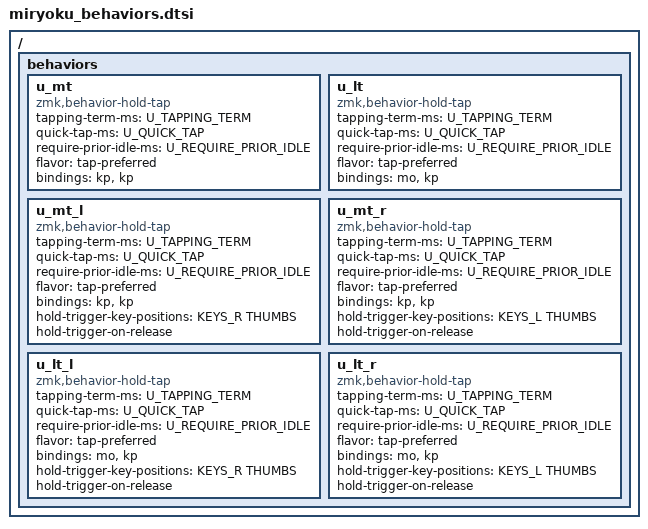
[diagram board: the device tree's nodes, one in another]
// Copyright 2022 Manna Harbour
// https://github.com/manna-harbour/miryoku

// Default key position definitions - can be overridden by keyboard-specific mappings
#if !defined(KEYS_L)
#define KEYS_L 0 1 2 3 4 10 11 12 13 14 20 21 22 23 24  // Left-hand keys
#endif
#if !defined(KEYS_R)
#define KEYS_R 5 6 7 8 9 15 16 17 18 19 25 26 27 28 29  // Right-hand keys
#endif
#if !defined(THUMBS)
#define THUMBS 30 31 32 33 34 35                        // Thumb keys
#endif

/ {
  behaviors {
    u_mt: u_mt {
      compatible = "zmk,behavior-hold-tap";
      #binding-cells = <2>;
      tapping-term-ms = <U_TAPPING_TERM>;
      quick-tap-ms = <U_QUICK_TAP>;
      require-prior-idle-ms = <U_REQUIRE_PRIOR_IDLE>;
      flavor = "tap-preferred";
      bindings = <&kp>, <&kp>;
    };
    u_lt: u_lt {
      compatible = "zmk,behavior-hold-tap";
      #binding-cells = <2>;
      tapping-term-ms = <U_TAPPING_TERM>;
      quick-tap-ms = <U_QUICK_TAP>;
      require-prior-idle-ms = <U_REQUIRE_PRIOR_IDLE>;
      flavor = "tap-preferred";
      bindings = <&mo>, <&kp>;
    };
    u_mt_l: u_mt_l {
      compatible = "zmk,behavior-hold-tap";
      #binding-cells = <2>;
      tapping-term-ms = <U_TAPPING_TERM>;
      quick-tap-ms = <U_QUICK_TAP>;
      require-prior-idle-ms = <U_REQUIRE_PRIOR_IDLE>;
      flavor = "tap-preferred";
      bindings = <&kp>, <&kp>;
      hold-trigger-key-positions = <KEYS_R THUMBS>;
      hold-trigger-on-release;
    };
    u_mt_r: u_mt_r {
      compatible = "zmk,behavior-hold-tap";
      #binding-cells = <2>;
      tapping-term-ms = <U_TAPPING_TERM>;
      quick-tap-ms = <U_QUICK_TAP>;
      require-prior-idle-ms = <U_REQUIRE_PRIOR_IDLE>;
      flavor = "tap-preferred";
      bindings = <&kp>, <&kp>;
      hold-trigger-key-positions = <KEYS_L THUMBS>;
      hold-trigger-on-release;
    };
    u_lt_l: u_lt_l {
      compatible = "zmk,behavior-hold-tap";
      #binding-cells = <2>;
      tapping-term-ms = <U_TAPPING_TERM>;
      quick-tap-ms = <U_QUICK_TAP>;
      require-prior-idle-ms = <U_REQUIRE_PRIOR_IDLE>;
      flavor = "tap-preferred";
      bindings = <&mo>, <&kp>;
      hold-trigger-key-positions = <KEYS_R THUMBS>;
      hold-trigger-on-release;
    };
    u_lt_r: u_lt_r {
      compatible = "zmk,behavior-hold-tap";
      #binding-cells = <2>;
      tapping-term-ms = <U_TAPPING_TERM>;
      quick-tap-ms = <U_QUICK_TAP>;
      require-prior-idle-ms = <U_REQUIRE_PRIOR_IDLE>;
      flavor = "tap-preferred";
      bindings = <&mo>, <&kp>;
      hold-trigger-key-positions = <KEYS_L THUMBS>;
      hold-trigger-on-release;
    };
  };
};
